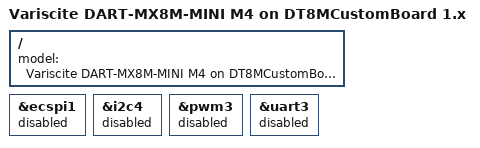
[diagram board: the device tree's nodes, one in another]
// SPDX-License-Identifier: (GPL-2.0+ OR MIT)
/*
 * Copyright 2019 NXP
 * Copyright 2019-2022 Variscite Ltd.
 */

#include "imx8mm-var-dart-dt8mcustomboard-legacy.dts"
#include "imx8mm-var-m4.dtsi"

/ {
	model = "Variscite DART-MX8M-MINI M4 on DT8MCustomBoard 1.x";
};

/*
 * ATTENTION: M4 may use the followings IPs:
 * ECSPI1, GPIO4, GPT1, I2C4, WDOG1, PWM3, SDMA1/3, UART3
 */

&ecspi1 {
	status = "disabled";
};

&i2c4 {
	status = "disabled";
};

&pwm3 {
	status = "disabled";
};

&uart3 {
	status = "disabled";
};
